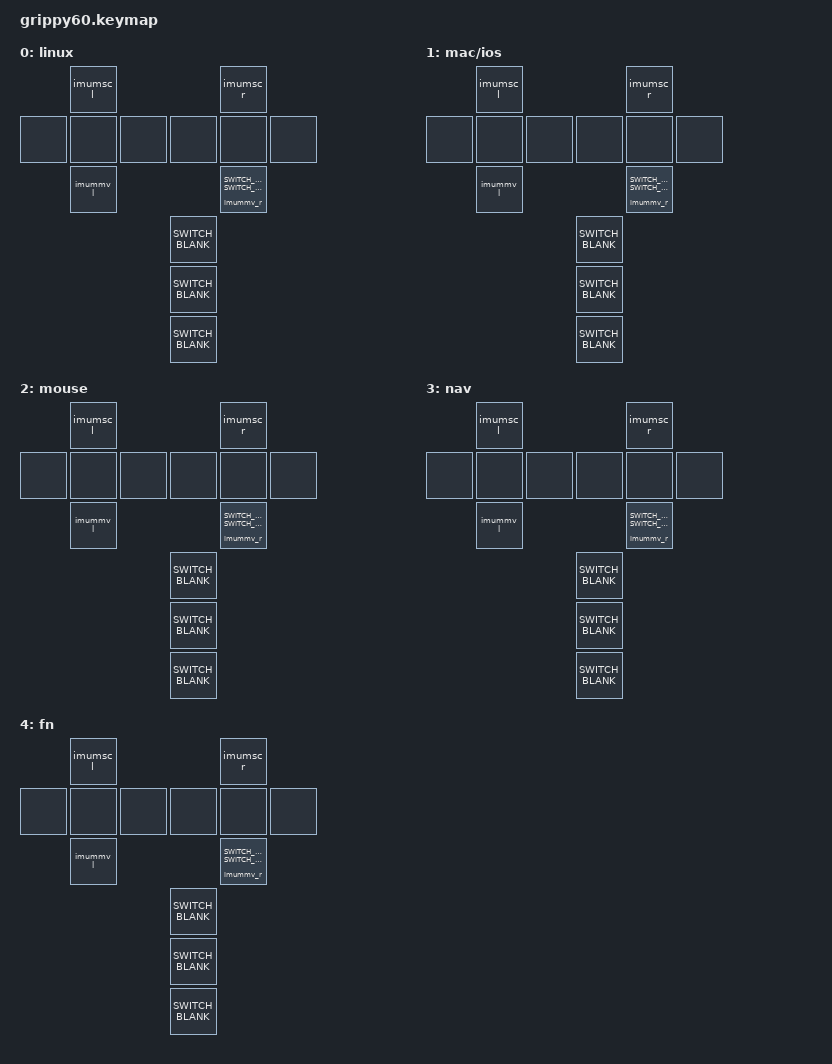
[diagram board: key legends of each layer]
#include <behaviors.dtsi>
#include <dt-bindings/zmk/keys.h>
#include <dt-bindings/zmk/bt.h>
#include "grippy60.h"

// CONFIG
#define DEFAULT_LAYER MACOS
#define COMBO_TIMEOUT TIMEOUT_NORMAL
#define CHORD_TIMEOUT TIMEOUT_NORMAL
#define STICKY_TIMEOUT TIMEOUT_XLONG
#define TAPPING_TERM_MS TIMEOUT_LONG

/ {
  behaviors {
    layer_on: toggle_on_layer {
      compatible = "zmk,behavior-toggle-layer";
      #binding-cells = <1>;
      display-name = "Toggle Layer On";
      toggle-mode = "on";
    };
    layer_off: toggle_off_layer {
      compatible = "zmk,behavior-toggle-layer";
      #binding-cells = <1>;
      display-name = "Toggle Layer Off";
      toggle-mode = "off";
    };

    ht: ht {
      compatible = "zmk,behavior-hold-tap";
      #binding-cells = <2>;
      tapping-term-ms = <TIMEOUT_NORMAL>;
      display-name = "Hold-Tap";
      bindings = <&kp>, <&kp>;
    };
  };

  combos {
    compatible = "zmk,combos";
    #include "combos.dtsi"
  };

  keymap {
    compatible = "zmk,keymap";

    /* We define layers here, but they are all unassigned.
     * Instead, I choose to use combos for assigning keys
     * with the exception of imu behavior since it is
     * source-specific.
     */
    linux {
      display-name = "linux";
      bindings = <
	      /* Outer thumb */
              &imumsc_l         &imumsc_r
        &none &none &none &none &none &none
              &imummv_l         &imummv_r
	      /* Inner thumb */ SWITCH_BLANK
	      /* Index       */ SWITCH_BLANK
	      /* Middle      */ SWITCH_BLANK
	      /* Ring        */ SWITCH_BLANK
	      /* Pinky       */ SWITCH_BLANK
      >;
    };
    mac {
      display-name = "mac/ios";
      bindings = <
	      /* Outer thumb */
              &imumsc_l         &imumsc_r
        &none &none &none &none &none &none
              &imummv_l         &imummv_r
	      /* Inner thumb */ SWITCH_BLANK
	      /* Index       */ SWITCH_BLANK
	      /* Middle      */ SWITCH_BLANK
	      /* Ring        */ SWITCH_BLANK
	      /* Pinky       */ SWITCH_BLANK
      >;
    };

    mouse {
      display-name = "mouse";
      bindings = <
	      /* Outer thumb */
              &imumsc_l         &imumsc_r
        &none &none &none &none &none &none
              &imummv_l         &imummv_r
	      /* Inner thumb */ SWITCH_BLANK
	      /* Index       */ SWITCH_BLANK
	      /* Middle      */ SWITCH_BLANK
	      /* Ring        */ SWITCH_BLANK
	      /* Pinky       */ SWITCH_BLANK
      >;
    };

    navigation {
      display-name = "nav";
      bindings = <
	      /* Outer thumb */
              &imumsc_l         &imumsc_r
        &none &none &none &none &none &none
              &imummv_l         &imummv_r
	      /* Inner thumb */ SWITCH_BLANK
	      /* Index       */ SWITCH_BLANK
	      /* Middle      */ SWITCH_BLANK
	      /* Ring        */ SWITCH_BLANK
	      /* Pinky       */ SWITCH_BLANK
      >;
    };

    function {
      display-name = "fn";
      bindings = <
	      /* Outer thumb */
              &imumsc_l         &imumsc_r
        &none &none &none &none &none &none
              &imummv_l         &imummv_r
	      /* Inner thumb */ SWITCH_BLANK
	      /* Index       */ SWITCH_BLANK
	      /* Middle      */ SWITCH_BLANK
	      /* Ring        */ SWITCH_BLANK
	      /* Pinky       */ SWITCH_BLANK
      >;
    };
  };
};

&lt {
    quick-tap-ms = <TIMEOUT_NORMAL>;
};

&sk {
  release-after-ms = <STICKY_TIMEOUT>;
  lazy;
};
